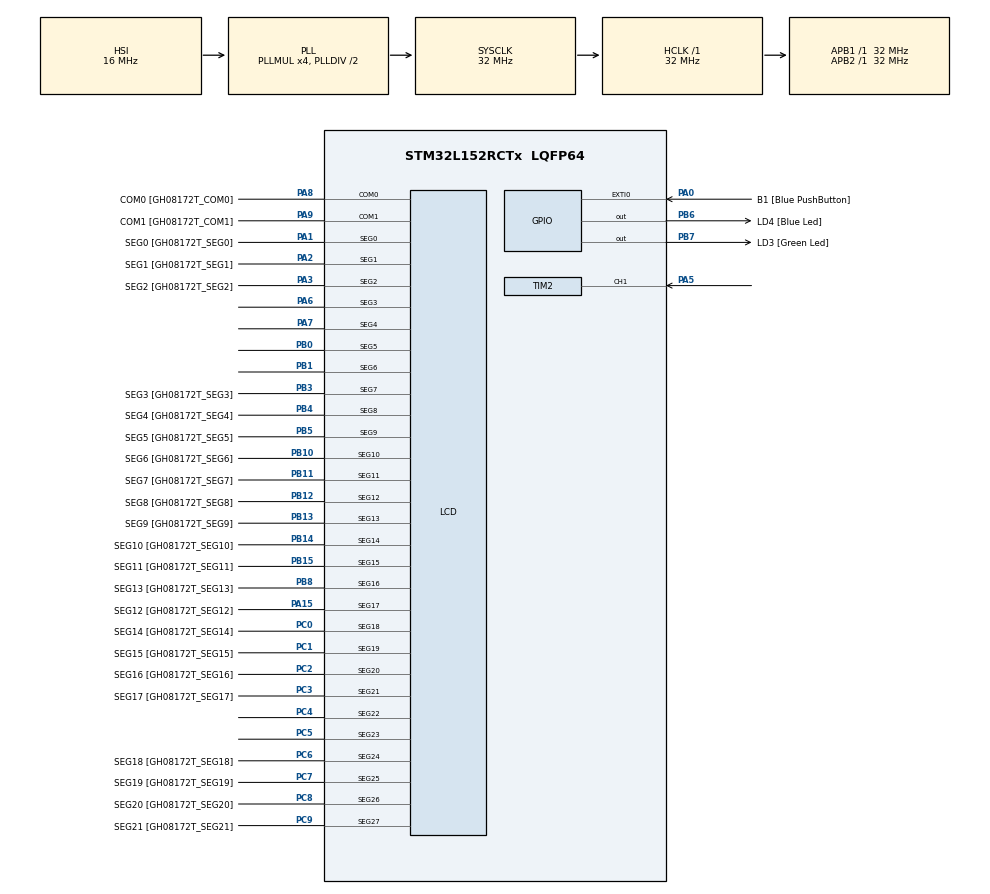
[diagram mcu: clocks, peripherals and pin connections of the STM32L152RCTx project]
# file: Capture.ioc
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Mcu.Family=STM32L1
Mcu.Name=STM32L152RCTx
Mcu.Package=LQFP64
NVIC.PriorityGroup=NVIC_PRIORITYGROUP_0
NVIC.TIM2_IRQn=true\:0\:0\:false\:false\:true\:true\:true\:true
PA0-WKUP1.GPIO_Label=B1 [Blue PushButton]
PA0-WKUP1.GPIO_ModeDefaultEXTI=GPIO_MODE_EVT_RISING
PA0-WKUP1.GPIO_PuPd=GPIO_NOPULL
PA0-WKUP1.Signal=GPXTI0
PA1.GPIO_Label=SEG0 [GH08172T_SEG0]
PA1.GPIO_Mode=GPIO_MODE_AF_PP
PA1.GPIO_PuPd=GPIO_NOPULL
PA1.GPIO_Speed=GPIO_SPEED_FREQ_LOW
PA1.Mode=SEG0
PA1.Signal=LCD_SEG0
PA10.GPIO_Label=COM2 [GH08172T_COM2]
PA10.GPIO_Mode=GPIO_MODE_AF_PP
PA10.GPIO_PuPd=GPIO_NOPULL
PA10.GPIO_Speed=GPIO_SPEED_FREQ_LOW
PA10.Signal=LCD_COM2
PA13.GPIO_Label=SWDIO
PA13.Signal=SYS_JTMS-SWDIO
PA14.GPIO_Label=SWCLK
PA14.Signal=SYS_JTCK-SWCLK
PA15.GPIO_Label=SEG12 [GH08172T_SEG12]
PA15.GPIO_Mode=GPIO_MODE_AF_PP
PA15.GPIO_PuPd=GPIO_NOPULL
PA15.GPIO_Speed=GPIO_SPEED_FREQ_LOW
PA15.Mode=SEG17
PA15.Signal=LCD_SEG17
PA2.GPIO_Label=SEG1 [GH08172T_SEG1]
PA2.GPIO_Mode=GPIO_MODE_AF_PP
PA2.GPIO_PuPd=GPIO_NOPULL
PA2.GPIO_Speed=GPIO_SPEED_FREQ_LOW
PA2.Mode=SEG1
PA2.Signal=LCD_SEG1
PA3.GPIO_Label=SEG2 [GH08172T_SEG2]
PA3.GPIO_Mode=GPIO_MODE_AF_PP
PA3.GPIO_PuPd=GPIO_NOPULL
PA3.GPIO_Speed=GPIO_SPEED_FREQ_LOW
PA3.Mode=SEG2
PA3.Signal=LCD_SEG2
PA5.Signal=S_TIM2_CH1_ETR
PA6.Mode=SEG3
PA6.Signal=LCD_SEG3
PA7.Mode=SEG4
PA7.Signal=LCD_SEG4
PA8.GPIO_Label=COM0 [GH08172T_COM0]
PA8.GPIO_Mode=GPIO_MODE_AF_PP
PA8.GPIO_PuPd=GPIO_NOPULL
PA8.GPIO_Speed=GPIO_SPEED_FREQ_LOW
PA8.Mode=1/2 Duty Cycle
PA8.Signal=LCD_COM0
PA9.GPIO_Label=COM1 [GH08172T_COM1]
PA9.GPIO_Mode=GPIO_MODE_AF_PP
PA9.GPIO_PuPd=GPIO_NOPULL
PA9.GPIO_Speed=GPIO_SPEED_FREQ_LOW
PA9.Mode=1/2 Duty Cycle
PA9.Signal=LCD_COM1
PB0.Mode=SEG5
PB0.Signal=LCD_SEG5
PB1.Mode=SEG6
PB1.Signal=LCD_SEG6
PB10.GPIO_Label=SEG6 [GH08172T_SEG6]
PB10.GPIO_Mode=GPIO_MODE_AF_PP
PB10.GPIO_PuPd=GPIO_NOPULL
PB10.GPIO_Speed=GPIO_SPEED_FREQ_LOW
PB10.Mode=SEG10
PB10.Signal=LCD_SEG10
PB11.GPIO_Label=SEG7 [GH08172T_SEG7]
PB11.GPIO_Mode=GPIO_MODE_AF_PP
PB11.GPIO_PuPd=GPIO_NOPULL
PB11.GPIO_Speed=GPIO_SPEED_FREQ_LOW
PB11.Mode=SEG11
PB11.Signal=LCD_SEG11
PB12.GPIO_Label=SEG8 [GH08172T_SEG8]
PB12.GPIO_Mode=GPIO_MODE_AF_PP
PB12.GPIO_PuPd=GPIO_NOPULL
PB12.GPIO_Speed=GPIO_SPEED_FREQ_LOW
PB12.Mode=SEG12
PB12.Signal=LCD_SEG12
PB13.GPIO_Label=SEG9 [GH08172T_SEG9]
PB13.GPIO_Mode=GPIO_MODE_AF_PP
PB13.GPIO_PuPd=GPIO_NOPULL
PB13.GPIO_Speed=GPIO_SPEED_FREQ_LOW
PB13.Mode=SEG13
PB13.Signal=LCD_SEG13
PB14.GPIO_Label=SEG10 [GH08172T_SEG10]
PB14.GPIO_Mode=GPIO_MODE_AF_PP
PB14.GPIO_PuPd=GPIO_NOPULL
PB14.GPIO_Speed=GPIO_SPEED_FREQ_LOW
PB14.Mode=SEG14
PB14.Signal=LCD_SEG14
PB15.GPIO_Label=SEG11 [GH08172T_SEG11]
PB15.GPIO_Mode=GPIO_MODE_AF_PP
PB15.GPIO_PuPd=GPIO_NOPULL
PB15.GPIO_Speed=GPIO_SPEED_FREQ_LOW
PB15.Mode=SEG15
PB15.Signal=LCD_SEG15
PB3.GPIO_Label=SEG3 [GH08172T_SEG3]
PB3.GPIO_Mode=GPIO_MODE_AF_PP
PB3.GPIO_PuPd=GPIO_NOPULL
PB3.GPIO_Speed=GPIO_SPEED_FREQ_LOW
PB3.Mode=SEG7
PB3.Signal=LCD_SEG7
PB4.GPIO_Label=SEG4 [GH08172T_SEG4]
PB4.GPIO_Mode=GPIO_MODE_AF_PP
PB4.GPIO_PuPd=GPIO_NOPULL
PB4.GPIO_Speed=GPIO_SPEED_FREQ_LOW
PB4.Mode=SEG8
PB4.Signal=LCD_SEG8
PB5.GPIO_Label=SEG5 [GH08172T_SEG5]
PB5.GPIO_Mode=GPIO_MODE_AF_PP
PB5.GPIO_PuPd=GPIO_NOPULL
PB5.GPIO_Speed=GPIO_SPEED_FREQ_LOW
PB5.Mode=SEG9
PB5.Signal=LCD_SEG9
PB6.GPIO_Label=LD4 [Blue Led]
PB6.GPIO_ModeDefaultOutputPP=GPIO_MODE_OUTPUT_PP
PB6.GPIO_PuPd=GPIO_NOPULL
PB6.GPIO_Speed=GPIO_SPEED_FREQ_LOW
PB6.Signal=GPIO_Output
PB7.GPIO_Label=LD3 [Green Led]
PB7.GPIO_ModeDefaultOutputPP=GPIO_MODE_OUTPUT_PP
PB7.GPIO_PuPd=GPIO_NOPULL
PB7.GPIO_Speed=GPIO_SPEED_FREQ_LOW
PB7.Signal=GPIO_Output
PB8.GPIO_Label=SEG13 [GH08172T_SEG13]
PB8.GPIO_Mode=GPIO_MODE_AF_PP
PB8.GPIO_PuPd=GPIO_NOPULL
PB8.GPIO_Speed=GPIO_SPEED_FREQ_LOW
PB8.Mode=SEG16
PB8.Signal=LCD_SEG16
PB9.GPIO_Label=COM3 [GH08172T_COM3]
PB9.GPIO_Mode=GPIO_MODE_AF_PP
PB9.GPIO_PuPd=GPIO_NOPULL
PB9.GPIO_Speed=GPIO_SPEED_FREQ_LOW
PB9.Signal=LCD_COM3
PC0.GPIO_Label=SEG14 [GH08172T_SEG14]
PC0.GPIO_Mode=GPIO_MODE_AF_PP
PC0.GPIO_PuPd=GPIO_NOPULL
PC0.GPIO_Speed=GPIO_SPEED_FREQ_LOW
PC0.Mode=SEG18
PC0.Signal=LCD_SEG18
PC1.GPIO_Label=SEG15 [GH08172T_SEG15]
PC1.GPIO_Mode=GPIO_MODE_AF_PP
PC1.GPIO_PuPd=GPIO_NOPULL
PC1.GPIO_Speed=GPIO_SPEED_FREQ_LOW
PC1.Mode=SEG19
PC1.Signal=LCD_SEG19
PC10.GPIO_Label=SEG22 [GH08172T_SEG22]
PC10.GPIO_Mode=GPIO_MODE_AF_PP
PC10.GPIO_PuPd=GPIO_NOPULL
PC10.GPIO_Speed=GPIO_SPEED_FREQ_LOW
PC10.Signal=LCD_SEG28
PC11.GPIO_Label=SEG23 [GH08172T_SEG23]
PC11.GPIO_Mode=GPIO_MODE_AF_PP
PC11.GPIO_PuPd=GPIO_NOPULL
PC11.GPIO_Speed=GPIO_SPEED_FREQ_LOW
PC11.Signal=LCD_SEG29
PC2.GPIO_Label=SEG16 [GH08172T_SEG16]
PC2.GPIO_Mode=GPIO_MODE_AF_PP
PC2.GPIO_PuPd=GPIO_NOPULL
PC2.GPIO_Speed=GPIO_SPEED_FREQ_LOW
PC2.Mode=SEG20
PC2.Signal=LCD_SEG20
PC3.GPIO_Label=SEG17 [GH08172T_SEG17]
PC3.GPIO_Mode=GPIO_MODE_AF_PP
PC3.GPIO_PuPd=GPIO_NOPULL
PC3.GPIO_Speed=GPIO_SPEED_FREQ_LOW
PC3.Mode=SEG21
PC3.Signal=LCD_SEG21
PC4.Mode=SEG22
PC4.Signal=LCD_SEG22
PC5.Mode=SEG23
PC5.Signal=LCD_SEG23
PC6.GPIO_Label=SEG18 [GH08172T_SEG18]
PC6.GPIO_Mode=GPIO_MODE_AF_PP
PC6.GPIO_PuPd=GPIO_NOPULL
PC6.GPIO_Speed=GPIO_SPEED_FREQ_LOW
PC6.Mode=SEG24
PC6.Signal=LCD_SEG24
PC7.GPIO_Label=SEG19 [GH08172T_SEG19]
PC7.GPIO_Mode=GPIO_MODE_AF_PP
PC7.GPIO_PuPd=GPIO_NOPULL
PC7.GPIO_Speed=GPIO_SPEED_FREQ_LOW
PC7.Mode=SEG25
PC7.Signal=LCD_SEG25
PC8.GPIO_Label=SEG20 [GH08172T_SEG20]
PC8.GPIO_Mode=GPIO_MODE_AF_PP
PC8.GPIO_PuPd=GPIO_NOPULL
PC8.GPIO_Speed=GPIO_SPEED_FREQ_LOW
PC8.Mode=SEG26
PC8.Signal=LCD_SEG26
PC9.GPIO_Label=SEG21 [GH08172T_SEG21]
PC9.GPIO_Mode=GPIO_MODE_AF_PP
PC9.GPIO_PuPd=GPIO_NOPULL
PC9.GPIO_Speed=GPIO_SPEED_FREQ_LOW
PC9.Mode=SEG27
PC9.Signal=LCD_SEG27
PH0-OSC_IN.Mode=HSE-External-Oscillator
PH0-OSC_IN.Signal=RCC_OSC_IN
PH1-OSC_OUT.Mode=HSE-External-Oscillator
PH1-OSC_OUT.Signal=RCC_OSC_OUT
ProjectManager.HeapSize=0x200
ProjectManager.StackSize=0x400
ProjectManager.TargetToolchain=EWARM V8.32
RCC.48MHZClocksFreq_Value=32000000
RCC.AHBFreq_Value=32000000
RCC.APB1Freq_Value=32000000
RCC.APB1TimFreq_Value=32000000
RCC.APB2Freq_Value=32000000
RCC.APB2TimFreq_Value=32000000
RCC.HCLKFreq_Value=32000000
RCC.HSE_VALUE=8000000
RCC.HSI_VALUE=16000000
RCC.LSE_VALUE=32768
RCC.MSI_VALUE=2097000
RCC.PLLMUL=RCC_PLL_MUL4
RCC.RTCClockSelection=RCC_RTCCLKSOURCE_LSI
RCC.RTCClockSelectionVirtual=RCC_RTCCLKSOURCE_LSE
RCC.SYSCLKFreq_VALUE=32000000
RCC.SYSCLKSource=RCC_SYSCLKSOURCE_PLLCLK
RCC.USBOutput=48000000
RCC.VCOOutputFreq_Value=64000000
SH.S_TIM2_CH1_ETR.0=TIM2_CH1,Input_Capture1_from_TI1
TIM2.Channel-Input_Capture1_from_TI1=TIM_CHANNEL_1
VP_LCD_LCD_mux.Mode=Multiplex
VP_TIM2_VS_ClockSourceINT.Mode=Internal
board=STM32L152C-DISCO

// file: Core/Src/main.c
/* USER CODE BEGIN Header */
/**
  ******************************************************************************
  * @file           : main.c
  * @brief          : Main program body
  ******************************************************************************
  * @attention
  *
  * Copyright (c) 2022 STMicroelectronics.
  * All rights reserved.
  *
  * This software is licensed under terms that can be found in the LICENSE file
  * in the root directory of this software component.
  * If no LICENSE file comes with this software, it is provided AS-IS.
  *
  ******************************************************************************
  */
/* USER CODE END Header */
#include "main.h"

 LCD_HandleTypeDef hlcd;

TIM_HandleTypeDef htim2;
uint16_t capturedValue = 0;

void SystemClock_Config(void);
static void MX_GPIO_Init(void);
static void MX_LCD_Init(void);
static void MX_TIM2_Init(void);

/* USER CODE BEGIN 0 */
void HAL_TIM_IC_CaptureCallback(TIM_HandleTypeDef *htim)
{
  capturedValue = HAL_TIM_ReadCapturedValue(&htim2, TIM_CHANNEL_1);
}
/* USER CODE END 0 */

int main(void)
{

  /* MCU Configuration--------------------------------------------------------*/

  /* Reset of all peripherals, Initializes the Flash interface and the Systick. */
  HAL_Init();

  /* Configure the system clock */
  SystemClock_Config();

  /* Initialize all configured peripherals */
  MX_GPIO_Init();
  MX_LCD_Init();
  MX_TIM2_Init();
  /* USER CODE BEGIN 2 */
  HAL_TIM_IC_Start_IT(&htim2, TIM_CHANNEL_1);
  /* USER CODE END 2 */

  /* Infinite loop */
  while (1)
  {

  }
}

void SystemClock_Config(void)
{
  RCC_OscInitTypeDef RCC_OscInitStruct = {0};
  RCC_ClkInitTypeDef RCC_ClkInitStruct = {0};
  RCC_PeriphCLKInitTypeDef PeriphClkInit = {0};

  /** Configure the main internal regulator output voltage
  */
  __HAL_PWR_VOLTAGESCALING_CONFIG(PWR_REGULATOR_VOLTAGE_SCALE1);

  /** Initializes the RCC Oscillators according to the specified parameters
  * in the RCC_OscInitTypeDef structure.
  */
  RCC_OscInitStruct.OscillatorType = RCC_OSCILLATORTYPE_HSI|RCC_OSCILLATORTYPE_LSI;
  RCC_OscInitStruct.HSIState = RCC_HSI_ON;
  RCC_OscInitStruct.HSICalibrationValue = RCC_HSICALIBRATION_DEFAULT;
  RCC_OscInitStruct.LSIState = RCC_LSI_ON;
  RCC_OscInitStruct.PLL.PLLState = RCC_PLL_ON;
  RCC_OscInitStruct.PLL.PLLSource = RCC_PLLSOURCE_HSI;
  RCC_OscInitStruct.PLL.PLLMUL = RCC_PLL_MUL4;
  RCC_OscInitStruct.PLL.PLLDIV = RCC_PLL_DIV2;
  if (HAL_RCC_OscConfig(&RCC_OscInitStruct) != HAL_OK)
  {
    Error_Handler();
  }

  /** Initializes the CPU, AHB and APB buses clocks
  */
  RCC_ClkInitStruct.ClockType = RCC_CLOCKTYPE_HCLK|RCC_CLOCKTYPE_SYSCLK
                              |RCC_CLOCKTYPE_PCLK1|RCC_CLOCKTYPE_PCLK2;
  RCC_ClkInitStruct.SYSCLKSource = RCC_SYSCLKSOURCE_PLLCLK;
  RCC_ClkInitStruct.AHBCLKDivider = RCC_SYSCLK_DIV1;
  RCC_ClkInitStruct.APB1CLKDivider = RCC_HCLK_DIV1;
  RCC_ClkInitStruct.APB2CLKDivider = RCC_HCLK_DIV1;

  if (HAL_RCC_ClockConfig(&RCC_ClkInitStruct, FLASH_LATENCY_1) != HAL_OK)
  {
    Error_Handler();
  }
  PeriphClkInit.PeriphClockSelection = RCC_PERIPHCLK_RTC|RCC_PERIPHCLK_LCD;
  PeriphClkInit.RTCClockSelection = RCC_RTCCLKSOURCE_LSI;
  PeriphClkInit.LCDClockSelection = RCC_RTCCLKSOURCE_LSI;

  if (HAL_RCCEx_PeriphCLKConfig(&PeriphClkInit) != HAL_OK)
  {
    Error_Handler();
  }
}

static void MX_LCD_Init(void)
{

  hlcd.Instance = LCD;
  hlcd.Init.Prescaler = LCD_PRESCALER_1;
  hlcd.Init.Divider = LCD_DIVIDER_16;
  hlcd.Init.Duty = LCD_DUTY_1_2;
  hlcd.Init.Bias = LCD_BIAS_1_4;
  hlcd.Init.VoltageSource = LCD_VOLTAGESOURCE_INTERNAL;
  hlcd.Init.Contrast = LCD_CONTRASTLEVEL_0;
  hlcd.Init.DeadTime = LCD_DEADTIME_0;
  hlcd.Init.PulseOnDuration = LCD_PULSEONDURATION_0;
  hlcd.Init.MuxSegment = LCD_MUXSEGMENT_ENABLE;
  hlcd.Init.BlinkMode = LCD_BLINKMODE_OFF;
  hlcd.Init.BlinkFrequency = LCD_BLINKFREQUENCY_DIV8;
  if (HAL_LCD_Init(&hlcd) != HAL_OK)
  {
    Error_Handler();
  }

}

static void MX_TIM2_Init(void)
{

  TIM_ClockConfigTypeDef sClockSourceConfig = {0};
  TIM_MasterConfigTypeDef sMasterConfig = {0};
  TIM_IC_InitTypeDef sConfigIC = {0};

  htim2.Instance = TIM2;
  htim2.Init.Prescaler = 0;
  htim2.Init.CounterMode = TIM_COUNTERMODE_UP;
  htim2.Init.Period = 65535;
  htim2.Init.ClockDivision = TIM_CLOCKDIVISION_DIV1;
  htim2.Init.AutoReloadPreload = TIM_AUTORELOAD_PRELOAD_DISABLE;
  if (HAL_TIM_Base_Init(&htim2) != HAL_OK)
  {
    Error_Handler();
  }
  sClockSourceConfig.ClockSource = TIM_CLOCKSOURCE_INTERNAL;
  if (HAL_TIM_ConfigClockSource(&htim2, &sClockSourceConfig) != HAL_OK)
  {
    Error_Handler();
  }
  if (HAL_TIM_IC_Init(&htim2) != HAL_OK)
  {
    Error_Handler();
  }
  sMasterConfig.MasterOutputTrigger = TIM_TRGO_RESET;
  sMasterConfig.MasterSlaveMode = TIM_MASTERSLAVEMODE_DISABLE;
  if (HAL_TIMEx_MasterConfigSynchronization(&htim2, &sMasterConfig) != HAL_OK)
  {
    Error_Handler();
  }
  sConfigIC.ICPolarity = TIM_INPUTCHANNELPOLARITY_RISING;
  sConfigIC.ICSelection = TIM_ICSELECTION_DIRECTTI;
  sConfigIC.ICPrescaler = TIM_ICPSC_DIV1;
  sConfigIC.ICFilter = 0;
  if (HAL_TIM_IC_ConfigChannel(&htim2, &sConfigIC, TIM_CHANNEL_1) != HAL_OK)
  {
    Error_Handler();
  }

}

static void MX_GPIO_Init(void)
{
  GPIO_InitTypeDef GPIO_InitStruct = {0};

  /* GPIO Ports Clock Enable */
  __HAL_RCC_GPIOC_CLK_ENABLE();
  __HAL_RCC_GPIOH_CLK_ENABLE();
  __HAL_RCC_GPIOA_CLK_ENABLE();
  __HAL_RCC_GPIOB_CLK_ENABLE();
  __HAL_RCC_GPIOD_CLK_ENABLE();

  /*Configure GPIO pin Output Level */
  HAL_GPIO_WritePin(GPIOB, LD4_Pin|LD3_Pin, GPIO_PIN_RESET);

  /*Configure GPIO pins : PC13 PC14 PC15 PC12 */
  GPIO_InitStruct.Pin = GPIO_PIN_13|GPIO_PIN_14|GPIO_PIN_15|GPIO_PIN_12;
  GPIO_InitStruct.Mode = GPIO_MODE_ANALOG;
  GPIO_InitStruct.Pull = GPIO_NOPULL;
  HAL_GPIO_Init(GPIOC, &GPIO_InitStruct);

  /*Configure GPIO pin : B1_Pin */
  GPIO_InitStruct.Pin = B1_Pin;
  GPIO_InitStruct.Mode = GPIO_MODE_EVT_RISING;
  GPIO_InitStruct.Pull = GPIO_NOPULL;
  HAL_GPIO_Init(B1_GPIO_Port, &GPIO_InitStruct);

  /*Configure GPIO pins : PA4 PA11 PA12 */
  GPIO_InitStruct.Pin = GPIO_PIN_4|GPIO_PIN_11|GPIO_PIN_12;
  GPIO_InitStruct.Mode = GPIO_MODE_ANALOG;
  GPIO_InitStruct.Pull = GPIO_NOPULL;
  HAL_GPIO_Init(GPIOA, &GPIO_InitStruct);

  /*Configure GPIO pin : PB2 */
  GPIO_InitStruct.Pin = GPIO_PIN_2;
  GPIO_InitStruct.Mode = GPIO_MODE_ANALOG;
  GPIO_InitStruct.Pull = GPIO_NOPULL;
  HAL_GPIO_Init(GPIOB, &GPIO_InitStruct);

  /*Configure GPIO pin : PD2 */
  GPIO_InitStruct.Pin = GPIO_PIN_2;
  GPIO_InitStruct.Mode = GPIO_MODE_ANALOG;
  GPIO_InitStruct.Pull = GPIO_NOPULL;
  HAL_GPIO_Init(GPIOD, &GPIO_InitStruct);

  /*Configure GPIO pins : LD4_Pin LD3_Pin */
  GPIO_InitStruct.Pin = LD4_Pin|LD3_Pin;
  GPIO_InitStruct.Mode = GPIO_MODE_OUTPUT_PP;
  GPIO_InitStruct.Pull = GPIO_NOPULL;
  GPIO_InitStruct.Speed = GPIO_SPEED_FREQ_LOW;
  HAL_GPIO_Init(GPIOB, &GPIO_InitStruct);

}

void Error_Handler(void)
{
  __disable_irq();
  while (1)
  {
  }
}
